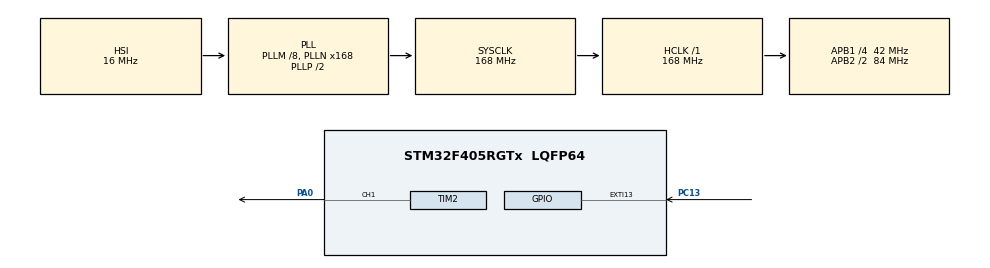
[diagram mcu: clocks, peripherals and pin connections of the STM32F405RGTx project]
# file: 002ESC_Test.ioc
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Mcu.Family=STM32F4
Mcu.Name=STM32F405RGTx
Mcu.Package=LQFP64
NVIC.EXTI15_10_IRQn=true\:1\:0\:true\:false\:true\:true\:true\:true
NVIC.PriorityGroup=NVIC_PRIORITYGROUP_4
PA0-WKUP.Signal=S_TIM2_CH1_ETR
PA13.Mode=JTAG_4_pins
PA13.Signal=SYS_JTMS-SWDIO
PA14.Mode=JTAG_4_pins
PA14.Signal=SYS_JTCK-SWCLK
PA15.Mode=JTAG_4_pins
PA15.Signal=SYS_JTDI
PB3.Mode=JTAG_4_pins
PB3.Signal=SYS_JTDO-SWO
PC13-ANTI_TAMP.GPIO_ModeDefaultEXTI=GPIO_MODE_IT_RISING
PC13-ANTI_TAMP.GPIO_PuPd=GPIO_PULLDOWN
PC13-ANTI_TAMP.Signal=GPXTI13
PC14-OSC32_IN.Mode=LSE-External-Oscillator
PC14-OSC32_IN.Signal=RCC_OSC32_IN
PC15-OSC32_OUT.Mode=LSE-External-Oscillator
PC15-OSC32_OUT.Signal=RCC_OSC32_OUT
PH0-OSC_IN.Mode=HSE-External-Oscillator
PH0-OSC_IN.Signal=RCC_OSC_IN
PH1-OSC_OUT.Mode=HSE-External-Oscillator
PH1-OSC_OUT.Signal=RCC_OSC_OUT
ProjectManager.HeapSize=0x200
ProjectManager.StackSize=0x400
ProjectManager.TargetToolchain=STM32CubeIDE
RCC.48MHZClocksFreq_Value=84000000
RCC.AHBFreq_Value=168000000
RCC.APB1CLKDivider=RCC_HCLK_DIV4
RCC.APB1Freq_Value=42000000
RCC.APB1TimFreq_Value=84000000
RCC.APB2CLKDivider=RCC_HCLK_DIV2
RCC.APB2Freq_Value=84000000
RCC.APB2TimFreq_Value=168000000
RCC.CortexFreq_Value=168000000
RCC.HCLKFreq_Value=168000000
RCC.HSE_VALUE=8000000
RCC.HSI_VALUE=16000000
RCC.PLLM=8
RCC.PLLN=168
RCC.SYSCLKFreq_VALUE=168000000
RCC.SYSCLKSource=RCC_SYSCLKSOURCE_PLLCLK
RCC.VCOOutputFreq_Value=336000000
SH.S_TIM2_CH1_ETR.0=TIM2_CH1,PWM Generation1 CH1
TIM2.AutoReloadPreload=TIM_AUTORELOAD_PRELOAD_ENABLE
TIM2.Channel-PWM\ Generation1\ CH1=TIM_CHANNEL_1
TIM2.Period=19999
TIM2.Prescaler=83
board=custom

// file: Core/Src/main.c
/* USER CODE BEGIN Header */
/**
  ******************************************************************************
  * @file           : main.c
  * @brief          : Main program body
  ******************************************************************************
  * @attention
  *
  * Copyright (c) 2026 STMicroelectronics.
  * All rights reserved.
  *
  * This software is licensed under terms that can be found in the LICENSE file
  * in the root directory of this software component.
  * If no LICENSE file comes with this software, it is provided AS-IS.
  *
  ******************************************************************************
  */
/* USER CODE END Header */
#include "main.h"

TIM_HandleTypeDef htim2;

/* USER CODE BEGIN PV */

uint8_t status = 0;

/* USER CODE END PV */

void SystemClock_Config(void);
static void MX_GPIO_Init(void);
static void MX_TIM2_Init(void);

int main(void)
{

  /* MCU Configuration--------------------------------------------------------*/

  /* Reset of all peripherals, Initializes the Flash interface and the Systick. */
  HAL_Init();

  /* Configure the system clock */
  SystemClock_Config();

  /* Initialize all configured peripherals */
  MX_GPIO_Init();
  MX_TIM2_Init();
  /* USER CODE BEGIN 2 */

  htim2.Instance->CCR1 = 999;

  HAL_TIM_PWM_Start(&htim2, TIM_CHANNEL_1);

  /* USER CODE END 2 */

  /* Infinite loop */
  /* USER CODE BEGIN WHILE */
  while (1)
  {

	  switch ( status )
	{
	  case 0:
	  {
		  htim2.Instance->CCR1 = 1000; // pwm with 5% duty circle
		  break;
	  }

	  case 1:
	  {
		  htim2.Instance->CCR1 = 2000; // pwm with 10% duty circle
		  break;
	  }

	  case 2:
	  {
		  htim2.Instance->CCR1 = 3000; // pwm with 10% duty circle
		  break;
	  }
	  default:
		  htim2.Instance->CCR1 = 999;
  }

    /* USER CODE END WHILE */

  }
}

void SystemClock_Config(void)
{
  RCC_OscInitTypeDef RCC_OscInitStruct = {0};
  RCC_ClkInitTypeDef RCC_ClkInitStruct = {0};

  /** Configure the main internal regulator output voltage
  */
  __HAL_RCC_PWR_CLK_ENABLE();
  __HAL_PWR_VOLTAGESCALING_CONFIG(PWR_REGULATOR_VOLTAGE_SCALE1);

  /** Initializes the RCC Oscillators according to the specified parameters
  * in the RCC_OscInitTypeDef structure.
  */
  RCC_OscInitStruct.OscillatorType = RCC_OSCILLATORTYPE_HSI;
  RCC_OscInitStruct.HSIState = RCC_HSI_ON;
  RCC_OscInitStruct.HSICalibrationValue = RCC_HSICALIBRATION_DEFAULT;
  RCC_OscInitStruct.PLL.PLLState = RCC_PLL_ON;
  RCC_OscInitStruct.PLL.PLLSource = RCC_PLLSOURCE_HSI;
  RCC_OscInitStruct.PLL.PLLM = 8;
  RCC_OscInitStruct.PLL.PLLN = 168;
  RCC_OscInitStruct.PLL.PLLP = RCC_PLLP_DIV2;
  RCC_OscInitStruct.PLL.PLLQ = 4;
  if (HAL_RCC_OscConfig(&RCC_OscInitStruct) != HAL_OK)
  {
    Error_Handler();
  }

  /** Initializes the CPU, AHB and APB buses clocks
  */
  RCC_ClkInitStruct.ClockType = RCC_CLOCKTYPE_HCLK|RCC_CLOCKTYPE_SYSCLK
                              |RCC_CLOCKTYPE_PCLK1|RCC_CLOCKTYPE_PCLK2;
  RCC_ClkInitStruct.SYSCLKSource = RCC_SYSCLKSOURCE_PLLCLK;
  RCC_ClkInitStruct.AHBCLKDivider = RCC_SYSCLK_DIV1;
  RCC_ClkInitStruct.APB1CLKDivider = RCC_HCLK_DIV4;
  RCC_ClkInitStruct.APB2CLKDivider = RCC_HCLK_DIV2;

  if (HAL_RCC_ClockConfig(&RCC_ClkInitStruct, FLASH_LATENCY_5) != HAL_OK)
  {
    Error_Handler();
  }
}

static void MX_TIM2_Init(void)
{

  TIM_MasterConfigTypeDef sMasterConfig = {0};
  TIM_OC_InitTypeDef sConfigOC = {0};

  htim2.Instance = TIM2;
  htim2.Init.Prescaler = 83;
  htim2.Init.CounterMode = TIM_COUNTERMODE_UP;
  htim2.Init.Period = 19999;
  htim2.Init.ClockDivision = TIM_CLOCKDIVISION_DIV1;
  htim2.Init.AutoReloadPreload = TIM_AUTORELOAD_PRELOAD_ENABLE;
  if (HAL_TIM_PWM_Init(&htim2) != HAL_OK)
  {
    Error_Handler();
  }
  sMasterConfig.MasterOutputTrigger = TIM_TRGO_RESET;
  sMasterConfig.MasterSlaveMode = TIM_MASTERSLAVEMODE_DISABLE;
  if (HAL_TIMEx_MasterConfigSynchronization(&htim2, &sMasterConfig) != HAL_OK)
  {
    Error_Handler();
  }
  sConfigOC.OCMode = TIM_OCMODE_PWM1;
  sConfigOC.Pulse = 0;
  sConfigOC.OCPolarity = TIM_OCPOLARITY_HIGH;
  sConfigOC.OCFastMode = TIM_OCFAST_DISABLE;
  if (HAL_TIM_PWM_ConfigChannel(&htim2, &sConfigOC, TIM_CHANNEL_1) != HAL_OK)
  {
    Error_Handler();
  }
  HAL_TIM_MspPostInit(&htim2);

}

static void MX_GPIO_Init(void)
{
  GPIO_InitTypeDef GPIO_InitStruct = {0};

  /* GPIO Ports Clock Enable */
  __HAL_RCC_GPIOC_CLK_ENABLE();
  __HAL_RCC_GPIOH_CLK_ENABLE();
  __HAL_RCC_GPIOA_CLK_ENABLE();
  __HAL_RCC_GPIOB_CLK_ENABLE();

  /*Configure GPIO pin : PC13 */
  GPIO_InitStruct.Pin = GPIO_PIN_13;
  GPIO_InitStruct.Mode = GPIO_MODE_IT_RISING;
  GPIO_InitStruct.Pull = GPIO_PULLDOWN;
  HAL_GPIO_Init(GPIOC, &GPIO_InitStruct);

  /* EXTI interrupt init*/
  HAL_NVIC_SetPriority(EXTI15_10_IRQn, 1, 0);
  HAL_NVIC_EnableIRQ(EXTI15_10_IRQn);

}

/* USER CODE BEGIN 4 */

void HAL_GPIO_EXTI_Callback(uint16_t GPIO_Pin)
{
	if(GPIO_Pin == GPIO_PIN_13)
	{
		status++;
		status%=3;
	}
}

/* USER CODE END 4 */

void Error_Handler(void)
{
  __disable_irq();
  while (1)
  {
  }
}
